VERSION ""

NS_ :

BS_:

BU_: Gateway ECU_Thermal ECU_BMS PDM_Actuator Diagnostic_Tool

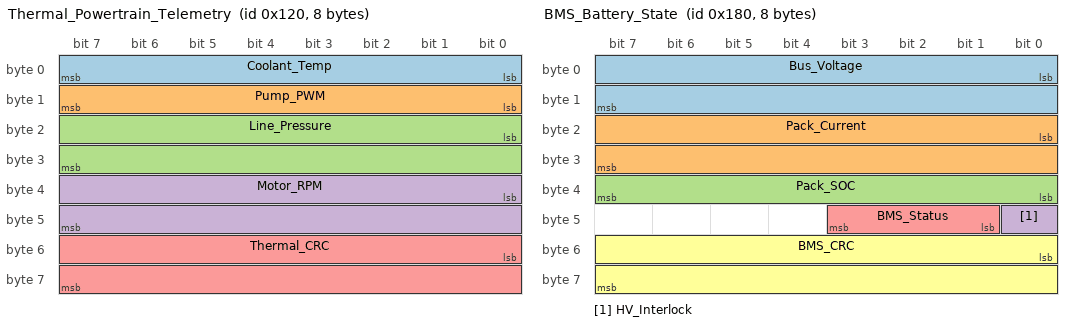
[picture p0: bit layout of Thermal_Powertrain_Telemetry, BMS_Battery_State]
BO_ 288 Thermal_Powertrain_Telemetry: 8 ECU_Thermal
 SG_ Coolant_Temp : 0|8@1+ (1,-40) [-40|215] "degC" Gateway,Diagnostic_Tool
 SG_ Pump_PWM : 8|8@1+ (1,0) [0|100] "%" Gateway,Diagnostic_Tool
 SG_ Line_Pressure : 16|16@1+ (0.1,0) [0|6553.5] "kPa" Gateway,Diagnostic_Tool
 SG_ Motor_RPM : 32|16@1+ (1,0) [0|20000] "rpm" Gateway,Diagnostic_Tool
 SG_ Thermal_CRC : 48|16@1+ (1,0) [0|65535] "" Gateway

BO_ 384 BMS_Battery_State: 8 ECU_BMS
 SG_ Bus_Voltage : 0|16@1+ (0.1,0) [0|1000] "V" Gateway,Diagnostic_Tool
 SG_ Pack_Current : 16|16@1- (0.1,0) [-3276.8|3276.7] "A" Gateway,Diagnostic_Tool
 SG_ Pack_SOC : 32|8@1+ (0.5,0) [0|100] "%" Gateway,Diagnostic_Tool
 SG_ HV_Interlock : 40|1@1+ (1,0) [0|1] "" Gateway,Diagnostic_Tool
 SG_ BMS_Status : 41|3@1+ (1,0) [0|7] "" Gateway,Diagnostic_Tool
 SG_ BMS_CRC : 48|16@1+ (1,0) [0|65535] "" Gateway

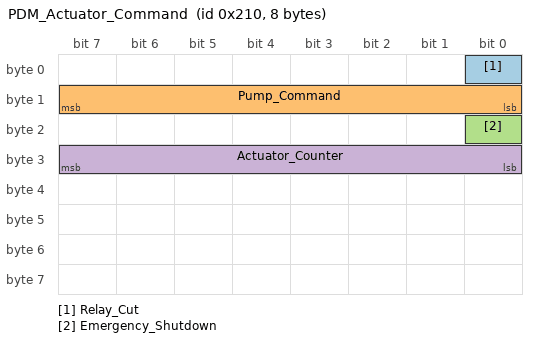
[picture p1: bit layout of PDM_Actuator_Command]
BO_ 528 PDM_Actuator_Command: 8 Gateway
 SG_ Relay_Cut : 0|1@1+ (1,0) [0|1] "" PDM_Actuator
 SG_ Pump_Command : 8|8@1+ (1,0) [0|100] "%" PDM_Actuator
 SG_ Emergency_Shutdown : 16|1@1+ (1,0) [0|1] "" PDM_Actuator
 SG_ Actuator_Counter : 24|8@1+ (1,0) [0|255] "" PDM_Actuator

BO_ 2016 UDS_Diagnostic_Request: 8 Diagnostic_Tool
 SG_ UDS_Req_Payload : 0|64@1+ (1,0) [0|0] "" Gateway

BO_ 2024 UDS_Diagnostic_Response: 8 Gateway
 SG_ UDS_Resp_Payload : 0|64@1+ (1,0) [0|0] "" Diagnostic_Tool

CM_ BO_ 288 "Thermal management and powertrain high frequency sensor telemetry";
CM_ SG_ 288 Coolant_Temp "Inverter and battery loop coolant temperature";
CM_ SG_ 288 Line_Pressure "Coolant loop hydraulic pressure";
CM_ BO_ 384 "High Voltage Battery Management System state";
CM_ SG_ 384 Bus_Voltage "High voltage traction pack bus voltage";
CM_ SG_ 384 HV_Interlock "High voltage safety interlock loop (1=Closed, 0=Open)";
CM_ BO_ 528 "Power Distribution Module critical actuator command frame";
CM_ SG_ 528 Relay_Cut "Emergency relay trip command (1=Cut/Trip, 0=Normal)";
